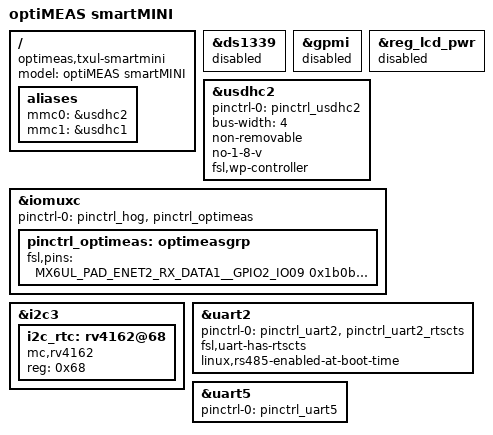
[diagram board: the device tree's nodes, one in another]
/*
 * Copyright 2015 Lothar Waßmann <LW@KARO-electronics.de>
 *
 * This file is dual-licensed: you can use it either under the terms
 * of the GPL or the X11 license, at your option. Note that this dual
 * licensing only applies to this file, and not this project as a
 * whole.
 *
 *  a) This file is free software; you can redistribute it and/or
 *     modify it under the terms of the GNU General Public License
 *     version 2 as published by the Free Software Foundation.
 *
 *     This file is distributed in the hope that it will be useful,
 *     but WITHOUT ANY WARRANTY; without even the implied warranty of
 *     MERCHANTABILITY or FITNESS FOR A PARTICULAR PURPOSE.  See the
 *     GNU General Public License for more details.
 *
 * Or, alternatively,
 *
 *  b) Permission is hereby granted, free of charge, to any person
 *     obtaining a copy of this software and associated documentation
 *     files (the "Software"), to deal in the Software without
 *     restriction, including without limitation the rights to use,
 *     copy, modify, merge, publish, distribute, sublicense, and/or
 *     sell copies of the Software, and to permit persons to whom the
 *     Software is furnished to do so, subject to the following
 *     conditions:
 *
 *     The above copyright notice and this permission notice shall be
 *     included in all copies or substantial portions of the Software.
 *
 *     THE SOFTWARE IS PROVIDED "AS IS", WITHOUT WARRANTY OF ANY KIND,
 *     EXPRESS OR IMPLIED, INCLUDING BUT NOT LIMITED TO THE WARRANTIES
 *     OF MERCHANTABILITY, FITNESS FOR A PARTICULAR PURPOSE AND
 *     NONINFRINGEMENT. IN NO EVENT SHALL THE AUTHORS OR COPYRIGHT
 *     HOLDERS BE LIABLE FOR ANY CLAIM, DAMAGES OR OTHER LIABILITY,
 *     WHETHER IN AN ACTION OF CONTRACT, TORT OR OTHERWISE, ARISING
 *     FROM, OUT OF OR IN CONNECTION WITH THE SOFTWARE OR THE USE OR
 *     OTHER DEALINGS IN THE SOFTWARE.
 */

/dts-v1/;
#include "imx6ull.dtsi"
#include "imx6ul-tx6ul.dtsi"

/ {
	model = "optiMEAS smartMINI";
	compatible = "optimeas,txul-smartmini", "karo,imx6ull-txul", "fsl,imx6ull";

	aliases {
		mmc0 = &usdhc2;
		mmc1 = &usdhc1;
	};
};

&ds1339 {
	status = "disabled";
};

&gpmi {
	status = "disabled";
};

&reg_lcd_pwr {
	status = "disabled";
};

&usdhc2 {
	pinctrl-names = "default";
	pinctrl-0 = <&pinctrl_usdhc2>;
	bus-width = <4>;
	non-removable;
	no-1-8-v;
	fsl,wp-controller;
	status = "okay";
};

&iomuxc {
	pinctrl-0 = <&pinctrl_hog &pinctrl_optimeas>;

	pinctrl_optimeas: optimeasgrp {
		fsl,pins = <
			MX6UL_PAD_ENET2_RX_DATA1__GPIO2_IO09		0x1b0b0 // IN:  SUSP_IND1		(Suspend output from USB hub)
			MX6UL_PAD_ENET2_TX_DATA0__GPIO2_IO11		0x1f0f0	// OUT: RS485_DE		(RS485 driver enable)
			MX6UL_PAD_ENET2_TX_EN__GPIO2_IO13		0x1f0f0	// OUT: RS485_/RE		(RS485 receiver enable)
			MX6UL_PAD_ENET2_RX_ER__GPIO2_IO15		0x1f0f0	// OUT: RS232_/EN		(RS232 transceiver enable)
			MX6UL_PAD_ENET2_RX_DATA0__GPIO2_IO08		0x1f0f0	// OUT: CAN0_STBY		(CAN0 transceiver standy)
			MX6UL_PAD_ENET2_RX_EN__GPIO2_IO10		0x1f0f0	// OUT: CAN1_STBY		(CAN1 transceiver standy)
			MX6UL_PAD_ENET2_TX_DATA1__GPIO2_IO12		0x1f0f0	// OUT: PWRKEY			(LTE modem power down)
			MX6UL_PAD_ENET2_TX_CLK__GPIO2_IO14		0x1b0b0	// IN:  GPS_1PPS		(PPS output from GPS module)
			MX6UL_PAD_CSI_DATA00__GPIO4_IO21		0x1f0f0	// OUT: GPIO_DOUT0		(User: digital output 0)
			MX6UL_PAD_CSI_DATA01__GPIO4_IO22		0x1f0f0	// OUT: GPIO_DOUT1		(User: digital output 1)
			MX6UL_PAD_CSI_DATA04__GPIO4_IO25		0x1b0b0	// IN:	GPIO_DIN0		(User: digital input 0)
			MX6UL_PAD_CSI_DATA05__GPIO4_IO26		0x1b0b0	// IN:	GPIO_DIN1		(User: digital input 1)
			MX6UL_PAD_CSI_VSYNC__GPIO4_IO19			0x1f0f0	// OUT: STATUS_LED0		(User: status LED 0)
			MX6UL_PAD_CSI_PIXCLK__GPIO4_IO18		0x1f0f0 // OUT: STATUS_LED1		(User: status LED 1)
			MX6UL_PAD_CSI_MCLK__GPIO4_IO17			0x1f0f0	// OUT: STATUS_LED2		(User: status LED 2)
			MX6UL_PAD_LCD_DATA00__GPIO3_IO05		0x1b0b0	// IN:  MC_OS_SELECT	(OS select signal from power controller)
			MX6UL_PAD_LCD_ENABLE__GPIO3_IO01		0x1b0b0	// IN:  VIRGIN			(Jumper for initial eMMC flashing)
			MX6UL_PAD_CSI_HSYNC__GPIO4_IO20			0x1f0f0 // OUT: MODEM_DCDC_ON	(LTE modem power supply)
		>;
	};
};

&i2c3 {
	i2c_rtc: rv4162@68 {
		compatible = "mc,rv4162";
		reg = <0x68>;
	};
};

&uart2 { /* ttymxc1 (RS232/485): pin63 / 64 */
	pinctrl-0 = <&pinctrl_uart2 &pinctrl_uart2_rtscts>;
	fsl,uart-has-rtscts;
    linux,rs485-enabled-at-boot-time;
};

&uart5 { /* ttymxc2 (GPS): pin67 / 68 */
	pinctrl-0 = <&pinctrl_uart5>;
};

